# HR_C7000_DM32 register map
Vendor: Dahua Technology (chip); Baofeng (radio product); Series: HR_C7000; File version: 0.1-dm32re-draft
CPU: other r0p0, little endian, no MPU, no FPU, 0 interrupt priority bits
Registers are 32-bit, read-write, reset 0x0 unless marked. A register's access mark holds for its fields unless they carry their own. Offsets are from the block's base; [hi:lo] are bit positions.

## ADC — CPU-side 10-bit ADC controller, 8 channels A-H in pairs per data register (DS §5.9, p.400-423). Distinct from the baseband RX ADC (SystemControl.ADC_CONTROL). FW: 23 sites in 2 code regions, reading all four data registers. The stock per-channel reader table at 0x030ada14 reads channel C as ADC_DATA_CD & 0x3ff (QEMU: dm32_adc.c). Which signal each channel carries on the DM-32 is not established here.
Base 0x140D0000
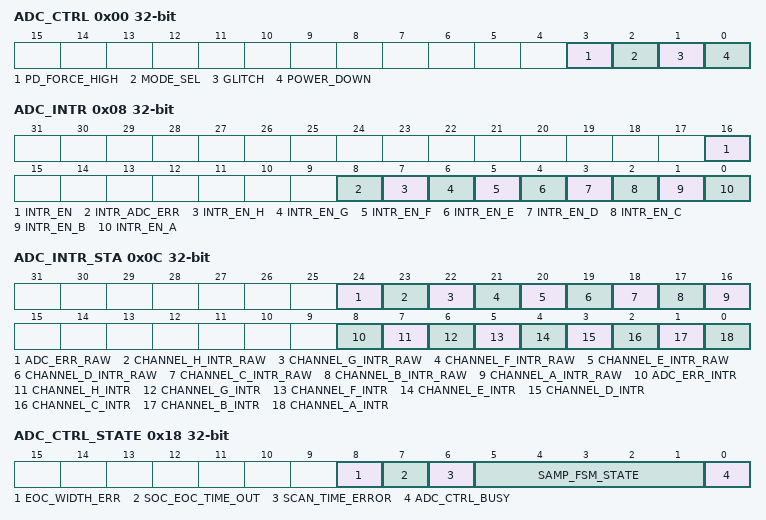
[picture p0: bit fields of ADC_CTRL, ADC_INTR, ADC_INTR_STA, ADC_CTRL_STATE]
0x00 ADC_CTRL — ADC Control registers. DS §5.9.5.1 p.411. FW: 0 reads, 3 writes. Reset 0x0 (DS).
  [3] PD_FORCE_HIGH — Write 1 to soft reset the ADC and controller. For normal operation, write 0 to clear it . [reset 0x0] [access RW]
  [2] MODE_SEL — Scan mode selection. 0 : Single scan; 1 : Continuous scan [reset 0x0] [access RW]
  [1] GLITCH — Whether to filter burrs. 0 : Do not filter burrs; 1 : Filter burrs. ( Single scan does not filter burrs. Need to filter burrs ) [reset 0x0] [access RW]
  [0] POWER_DOWN — Whether to support low power mode. 0 : not supported; 1 : supported [reset 0x0] [access RW]
0x04 ADC_INTR_DELTA — ADC Interruption error range. DS §5.9.5.2 p.411. Reset 0x0 (DS).
  [9:0] ADC_DATA_DELTA — Set the interrupt error range. The controller can trigger data interrupt and output data only when the difference between the sampled data and the ADC_INTR_THRESHOLE (0x24) register configuration value is greater than ( not equal to ) . Figure 50 . [reset 0x0] [access RW]
0x08 ADC_INTR — ADC Interrupt Control Register. DS §5.9.5.3 p.411. FW: 0 reads, 1 write. Reset 0x0 (DS).
  [16] INTR_EN — Global interrupt enable. 1 : enable ; 0 : disable [reset 0x0] [access RW]
  [8] INTR_ADC_ERR — ADC abnormal interrupt enable [reset 0x0] [access RW]
  [7] INTR_EN_H — CHH scan valid value interrupt enable. 1 : enable ; 0 : disable [reset 0x0] [access RW]
  [6] INTR_EN_G — CHG scan valid value interrupt enable. 1 : enable ; 0 : disable [reset 0x0] [access RW]
  [5] INTR_EN_F — CHF scan valid value interrupt enable. 1 : enable ; 0 : disable [reset 0x0] [access RW]
  [4] INTR_EN_E — CHE scan valid value interrupt enable. 1 : enable ; 0 : disable [reset 0x0] [access RW]
  [3] INTR_EN_D — CHD scan effective value interrupt enable. 1 : enable ; 0 : disable [reset 0x0] [access RW]
  [2] INTR_EN_C — CHC scan valid value interrupt enable. 1 : enable ; 0 : disable [reset 0x0] [access RW]
  [1] INTR_EN_B — CHB scan valid value interrupt enable. 1 : enable ; 0 : disable [reset 0x0] [access RW]
  [0] INTR_EN_A — CHA scan valid value interrupt enable. 1 : enable ; 0 : disable [reset 0x0] [access RW]
0x0C ADC_INTR_STA ro — ADC Interrupt Status Register. DS §5.9.5.4 p.413.
  [24] ADC_ERR_RAW — Unmasked ADC exception interrupt, software reads 0 the EOC signal does not appear 11 cycles after the SOC signal . [reset 0x0] [access RO]
  [23] CHANNEL_H_INTR_RAW — Unmasked channel H interrupt flag, software reads 0. 0 : No interrupt, 1 : Interrupt [reset 0x0] [access RO]
  [22] CHANNEL_G_INTR_RAW — Unmasked channel G interrupt flag, software reads 0. 0 : No interrupt, 1 : Interrupt [reset 0x0] [access RO]
  [21] CHANNEL_F_INTR_RAW — Unmasked channel F interrupt flag, software reads 0. 0 : No interrupt, 1 : Interrupt [reset 0x0] [access RO]
  [20] CHANNEL_E_INTR_RAW — Unmasked channel E interrupt flag, software reads 0. 0 : No interrupt, 1 : Interrupt [reset 0x0] [access RO]
  [19] CHANNEL_D_INTR_RAW — Unmasked channel D interrupt flag, software reads 0. 0 : No interrupt, 1 : Interrupt [reset 0x0] [access RO]
  [18] CHANNEL_C_INTR_RAW — Unmasked channel C interrupt flag, software reads 0. 0 : No interrupt, 1 : Interrupt [reset 0x0] [access RO]
  [17] CHANNEL_B_INTR_RAW — Unmasked channel B interrupt flag, software reads 0. 0 : No interrupt, 1 : Interrupt [reset 0x0] [access RO]
  [16] CHANNEL_A_INTR_RAW — Unmasked channel A interrupt flag, software reads 0. [reset 0x0] [access RO]
  [8] ADC_ERR_INTR — ADC abnormal interrupt, software reads clear 0 is triggered when the EOC signal does not appear in the 11th cycle after the SOC signal . [reset 0x0] [access RO]
  [7] CHANNEL_H_INTR — Channel H interrupt flag, software reads 0. 0 : No interrupt, 1 : Interrupt [reset 0x0] [access RO]
  [6] CHANNEL_G_INTR — Channel G interrupt flag, software reads 0. 0 : No interrupt, 1 : Interrupt [reset 0x0] [access RO]
  [5] CHANNEL_F_INTR — Channel F interrupt flag, software reads 0. 0 : No interrupt, 1 : Interrupt [reset 0x0] [access RO]
  [4] CHANNEL_E_INTR — Channel E interrupt flag, software reads 0. 0 : No interrupt, 1 : Interrupt [reset 0x0] [access RO]
  [3] CHANNEL_D_INTR — Channel D interrupt flag, software reads 0. 0 : No interrupt, 1 : Interrupt [reset 0x0] [access RO]
  [2] CHANNEL_C_INTR — Channel C interrupt flag, software reads 0. 0 : No interrupt, 1 : Interrupt [reset 0x0] [access RO]
  [1] CHANNEL_B_INTR — Channel B interrupt flag, software reads 0. 0 : No interrupt, 1 : Interrupt [reset 0x0] [access RO]
  [0] CHANNEL_A_INTR — Channel A interrupt flag, software reads 0. 0 : No interrupt, 1 : Interrupt [reset 0x0] [access RO]
0x10 ADC_SCAN_TIME reset 0x2C — ADC Scan interval setting. DS §5.9.5.5 p.415. Reset 0x2c (DS).
  [31:0] SCAN_TIME — Scan time interval setting, in units of clk number. The minimum configuration value is ( a d c _ e o c _ d _ t i m e + 1 2 , decimal number ) . If it is less than the minimum value, it is calculated according to the minimum value , and A DC_C T R L _ STAT E [ 3 ] is set, and the 0 x 2 0 register SCAN_TIME_ERR is set . Note : Before configuring this register, the 0 x 3 4 register must be configured first . [reset 0x2c] [access RW]
0x14 ADC_START wo — ADC start up. DS §5.9.5.6 p.415. FW: 0 reads, 1 write. Reset 0x0 (DS).
  [0] ADC_START — Write 1 to start the adc_ctrl module. In single scan mode, the next beat of the EOC signal will clear this bit to 0 ; in continuous scan mode, the adc_ctrl_stop register A write enable signal will clear this bit to 0. [reset 0x0] [access WO]
0x18 ADC_CTRL_STATE — ADC Control and Status Registers. DS §5.9.5.7 p.415. FW: 3 reads, 0 writes. Reset 0x0 (DS).
  [8] EOC_WIDTH_ERR — Set when the EOC signal width is greater than one clk . Cleared to 0 for any value . [reset 0x0] [access R/W]
  [7] SOC_EOC_TIME_OUT — Set when the interval between SOC and EOC is not equal to 11 clks . Write any value to clear 0. [reset 0x0] [access R/W]
  [6] SCAN_TIME_ERROR — The ADC_SCAN_TIME register configuration value is less than the minimum value. The meaning value is cleared to 0 . [reset 0x0] [access R/W]
  [5:1] SAMP_FSM_STATE ro — ADC_CTRL sampling data state machine state 9 : transition state, G_SAMPLE_S 8 : Sampling channel H data, G_SAMPLE_H . 7 : Sampling channel G data, G_SAMPLE_G . 6 : Sampling channel F data, G_SAMPLE_F . 5 : Sampling channel E data, G_SAMPLE_E . 4 : Sampling channel D data, G_SAMPLE_D . 3 : Sampling channel C status, G_SAMPLE_C . 2 : Sampling channel B status, G_SAMPLE_B . 1 : Sampling channel A status, G_SAMPLE_A . 0 : Idle state, G_IDLE [reset 0x0] [access RO]
  [0] ADC_CTRL_BUSY ro — ADC_CTRL module status indication. 0 : idle 1 : busy [reset 0x0] [access RO]
0x1C ADC_INTR_THRESHOLD — ADC Interrupt initial value. DS §5.9.5.8 p.417. Printed ADC_INTR_THRESHOLE (typo); the reserved row is printed [31:0], overlapping the field. Reset 0x0 (DS).
  [9:0] ADC_INTR_THRESHOLD — Interrupt reference value: an interrupt is raised when |conversion - this| exceeds ADC_INTR_DELTA [reset 0x0] [access RW]
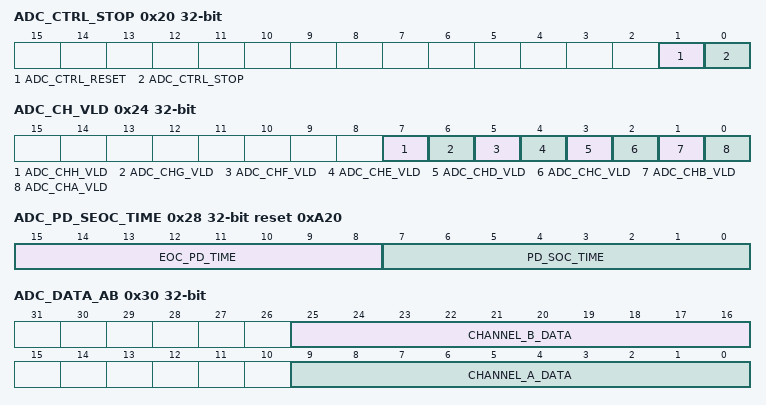
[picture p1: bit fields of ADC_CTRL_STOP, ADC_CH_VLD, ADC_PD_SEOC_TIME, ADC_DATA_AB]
0x20 ADC_CTRL_STOP wo — ADC Configuration registers. DS §5.9.5.9 p.417. FW: 0 reads, 3 writes. Reset 0x0 (DS).
  [1] ADC_CTRL_RESET — Write 1 to soft reset the controller, self- clearing [reset 0x0] [access WO]
  [0] ADC_CTRL_STOP — Only works in continuous scan mode. In continuous scan mode, it stops automatically scanning after scanning the last valid channel and clears itself to 0. (In continuous scan mode, writing 1 to this register can stop the automatic scanning function of adc_ctrl . It is necessary to rewrite the ADC_START and ADC_CH_VLD registers . to restart automatic scanning ) [reset 0x0] [access WO]
0x24 ADC_CH_VLD — ADC Channel Configuration Register. DS §5.9.5.10 p.419. FW: 0 reads, 2 writes. Note: Single scan mode, ADC_CH_VLD Only the lowest-order channel is valid; when scanning multiple times, scan from the lowest-order channel to the highest-order channel in sequence. Note: in single-scan mode only the lowest enabled channel is converted; in continuous mode channels are scanned lowest to highest. Reset 0x0 (DS).
  [7] ADC_CHH_VLD — In continuous scan mode, whether channel H is valid. 0 : invalid; 1 : valid. [reset 0x0] [access RW]
  [6] ADC_CHG_VLD — In continuous scan mode, is channel G valid? 0 : invalid; 1 : valid. [reset 0x0] [access RW]
  [5] ADC_CHF_VLD — In continuous scan mode, is channel F valid? 0 : invalid; 1 : valid. [reset 0x0] [access RW]
  [4] ADC_CHE_VLD — In continuous scan mode, is channel E valid? 0 : invalid; 1 : valid. [reset 0x0] [access RW]
  [3] ADC_CHD_VLD — In continuous scan mode, whether channel D is valid. 0 : invalid; 1 : valid. [reset 0x0] [access RW]
  [2] ADC_CHC_VLD — In continuous scan mode, is channel C valid? 0 : invalid; 1 : valid. [reset 0x0] [access RW]
  [1] ADC_CHB_VLD — In continuous scan mode, whether channel B is valid. 0 : invalid; 1 : valid. [reset 0x0] [access RW]
  [0] ADC_CHA_VLD — In continuous scan mode, whether channel A is valid. 0: invalid; 1: valid [reset 0x0] [access RW]
0x28 ADC_PD_SEOC_TIME reset 0xA20 — ADC Power-off time register. DS §5.9.5.11 p.419. FW: 0 reads, 1 write. Reset 0xa20 (DS).
  [15:8] EOC_PD_TIME — EOC and the rising edge of PD . the configured value is smaller than the default value, the default value is used. [reset 0xa] [access RW]
  [7:0] PD_SOC_TIME — SOC and the falling edge of PD . the configured value is smaller than the default value, the default value is used. [reset 0x20] [access RW]
0x2C ADC_P2S_EN — ADC Serial data output register. DS §5.9.5.12 p.419. FW: 0 reads, 1 write. Reset 0x0 (DS).
  [0] ADC_P2S_EN — Enables serial output of sampled data, for debugging only. 1 : enable ; 0 : disable [reset 0x0] [access RW]
0x30 ADC_DATA_AB ro — ADC Channel AB Scan Value. DS §5.9.5.13 p.420. FW: 2 reads, 0 writes. Reset 0x0 (DS).
  [25:16] CHANNEL_B_DATA — Channel B scan value [reset 0x0] [access RO]
  [9:0] CHANNEL_A_DATA — Channel A scan value [reset 0x0] [access RO]
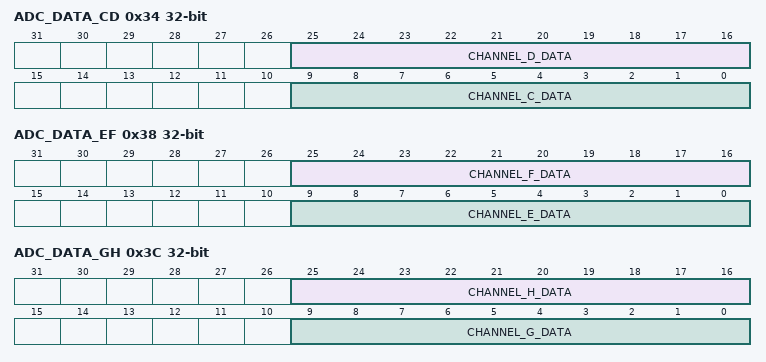
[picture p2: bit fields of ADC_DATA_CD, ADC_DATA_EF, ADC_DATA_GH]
0x34 ADC_DATA_CD ro — ADC Channel CD Scan Value. DS §5.9.5.14 p.421. FW: 2 reads, 0 writes. Reset 0x0 (DS).
  [25:16] CHANNEL_D_DATA — Channel D scan value [reset 0x0] [access RO]
  [9:0] CHANNEL_C_DATA — Channel C scan value [reset 0x0] [access RO]
0x38 ADC_DATA_EF ro — ADC Channel EF Scan Value. DS §5.9.5.15 p.421. FW: 2 reads, 0 writes. Reset 0x0 (DS).
  [25:16] CHANNEL_F_DATA — Channel F scan value [reset 0x0] [access RO]
  [9:0] CHANNEL_E_DATA — Channel E scan value [reset 0x0] [access RO]
0x3C ADC_DATA_GH ro — ADC Channel GH Scan Value. DS §5.9.5.16 p.421. FW: 2 reads, 0 writes. Reset 0x0 (DS).
  [25:16] CHANNEL_H_DATA — Channel H scan value [reset 0x0] [access RO]
  [9:0] CHANNEL_G_DATA — Channel G scan value [reset 0x0] [access RO]
0x40 ADC_CTRL_VERID ro reset 0x20151216 — ADC Version Register. DS §5.9.5.17 p.421. Reset 0x20151216 (DS).
  [31:0] ADC_CTRL_VERID — Controller version number (for debugging only ) [reset 0x20151216] [access RO]
0x44 ADC_DIR_DAT_OP ro — ADC EOC Then directly output ADC. DS §5.9.5.18 p.421. Reset 0x0 (DS).
  [9:0] ADC_DIR_DAT_OP — ADC data directly after EOC (for debug only ) [reset 0x0] [access RO]
